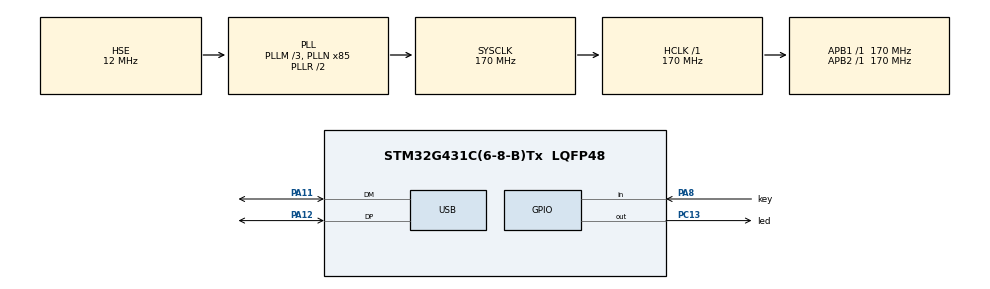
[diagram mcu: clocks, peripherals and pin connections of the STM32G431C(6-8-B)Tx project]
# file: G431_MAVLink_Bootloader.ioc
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CRC.CRCLength=CRC_POLYLENGTH_16B
CRC.DefaultInitValueUse=DEFAULT_INIT_VALUE_DISABLE
CRC.DefaultPolynomialUse=DEFAULT_POLYNOMIAL_DISABLE
CRC.InputDataInversionMode=CRC_INPUTDATA_INVERSION_NONE
CRC.OutputDataInversionMode=CRC_OUTPUTDATA_INVERSION_DISABLE
IWDG.Prescaler=IWDG_PRESCALER_64
IWDG.Reload=500
Mcu.Family=STM32G4
Mcu.Name=STM32G431C(6-8-B)Tx
Mcu.Package=LQFP48
NVIC.PriorityGroup=NVIC_PRIORITYGROUP_4
NVIC.TIM6_DAC_IRQn=true\:10\:0\:true\:false\:true\:true\:true\:true
NVIC.USB_LP_IRQn=true\:0\:0\:false\:false\:true\:false\:true\:true
PA11.Mode=Device
PA11.Signal=USB_DM
PA12.Mode=Device
PA12.Signal=USB_DP
PA13.Mode=Serial_Wire
PA13.Signal=SYS_JTMS-SWDIO
PA14.Mode=Serial_Wire
PA14.Signal=SYS_JTCK-SWCLK
PA8.GPIO_Label=key
PA8.GPIO_PuPd=GPIO_PULLUP
PA8.Signal=GPIO_Input
PC13.GPIO_Label=led
PC13.GPIO_PuPd=GPIO_PULLUP
PC13.PinState=GPIO_PIN_SET
PC13.Signal=GPIO_Output
PF0-OSC_IN.Mode=HSE-External-Oscillator
PF0-OSC_IN.Signal=RCC_OSC_IN
PF1-OSC_OUT.Mode=HSE-External-Oscillator
PF1-OSC_OUT.Signal=RCC_OSC_OUT
ProjectManager.HeapSize=0x200
ProjectManager.StackSize=0x400
ProjectManager.TargetToolchain=CMake
RCC.ADC12Freq_Value=170000000
RCC.AHBFreq_Value=170000000
RCC.APB1Freq_Value=170000000
RCC.APB1TimFreq_Value=170000000
RCC.APB2Freq_Value=170000000
RCC.APB2TimFreq_Value=170000000
RCC.CK48CLockSelection=RCC_USBCLKSOURCE_HSI48
RCC.CortexFreq_Value=170000000
RCC.EXTERNAL_CLOCK_VALUE=12288000
RCC.HCLKFreq_Value=170000000
RCC.HSE_VALUE=12000000
RCC.HSI48_VALUE=48000000
RCC.HSI_VALUE=16000000
RCC.LSE_VALUE=32768
RCC.PLLM=RCC_PLLM_DIV3
RCC.PLLN=85
RCC.PLLSourceVirtual=RCC_PLLSOURCE_HSE
RCC.SYSCLKFreq_VALUE=170000000
RCC.SYSCLKSource=RCC_SYSCLKSOURCE_PLLCLK
RCC.USBFreq_Value=48000000
RCC.VCOOutputFreq_Value=340000000
TIM6.AutoReloadPreload=TIM_AUTORELOAD_PRELOAD_ENABLE
TIM6.Dithering=Disable
TIM6.PeriodNoDither=1000-1
TIM6.Prescaler=170-1
USB_DEVICE.CLASS_NAME_FS=CDC
USB_DEVICE.VirtualMode=Cdc
USB_DEVICE.VirtualModeFS=Cdc_FS
VP_CRC_VS_CRC.Mode=CRC_Activate
VP_IWDG_VS_IWDG.Mode=IWDG_Activate
VP_SYS_VS_DBSignals.Mode=DisableDeadBatterySignals
VP_TIM6_VS_ClockSourceINT.Mode=Enable_Timer
VP_USB_DEVICE_VS_USB_DEVICE_CDC_FS.Mode=CDC_FS
board=custom

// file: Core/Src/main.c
/* USER CODE BEGIN Header */
/**
  ******************************************************************************
  * @file           : main.c
  * @brief          : Main program body
  ******************************************************************************
  * @attention
  *
  * Copyright (c) 2026 STMicroelectronics.
  * All rights reserved.
  *
  * This software is licensed under terms that can be found in the LICENSE file
  * in the root directory of this software component.
  * If no LICENSE file comes with this software, it is provided AS-IS.
  *
  ******************************************************************************
  */
/* USER CODE END Header */
#include "main.h"
#include "crc.h"
#include "iwdg.h"
#include "tim.h"
#include "usb_device.h"
#include "gpio.h"

/* USER CODE BEGIN Includes */
#include "task_fsm.h"
/* USER CODE END Includes */

void SystemClock_Config(void);

int main(void)
{

  /* MCU Configuration--------------------------------------------------------*/

  /* Reset of all peripherals, Initializes the Flash interface and the Systick. */
  HAL_Init();

  /* Configure the system clock */
  SystemClock_Config();

  /* Initialize all configured peripherals */
  MX_GPIO_Init();
  MX_USB_Device_Init();
  MX_CRC_Init();
  MX_IWDG_Init();
  MX_TIM6_Init();
  /* USER CODE BEGIN 2 */
  // 启动1ms定时器
  HAL_TIM_Base_Start_IT(&htim6);

  // 初始化LED
  led = LED_Init(led_GPIO_Port,  led_Pin,  LED_POLARITY_LOW);
  // 初始化LED状态机
  led_fsm = LED_FSM_Init(&led);

  YMODEM_Init(&ymodem_fsm);
  /* USER CODE END 2 */

  /* Infinite loop */
  while (1)
  {

    /* USER CODE BEGIN 3 */
    uint32_t tick = HAL_GetTick();
    static uint32_t tick_iwdg = 0;

    tesk_fsm(&task_fsm, tick);
    // 运行LED状态机
    LED_FSM_Run(&led_fsm, tick);

    // 700ms喂狗(复位周期1000ms)
    if (get_tick_diff(tick, tick_iwdg) >= 700)
    {
      tick_iwdg = tick;
      HAL_IWDG_Refresh(&hiwdg);
    }
  }
  /* USER CODE END 3 */
}

void SystemClock_Config(void)
{
  RCC_OscInitTypeDef RCC_OscInitStruct = {0};
  RCC_ClkInitTypeDef RCC_ClkInitStruct = {0};

  /** Configure the main internal regulator output voltage
  */
  HAL_PWREx_ControlVoltageScaling(PWR_REGULATOR_VOLTAGE_SCALE1_BOOST);

  /** Initializes the RCC Oscillators according to the specified parameters
  * in the RCC_OscInitTypeDef structure.
  */
  RCC_OscInitStruct.OscillatorType = RCC_OSCILLATORTYPE_HSI48|RCC_OSCILLATORTYPE_LSI
                              |RCC_OSCILLATORTYPE_HSE;
  RCC_OscInitStruct.HSEState = RCC_HSE_ON;
  RCC_OscInitStruct.LSIState = RCC_LSI_ON;
  RCC_OscInitStruct.HSI48State = RCC_HSI48_ON;
  RCC_OscInitStruct.PLL.PLLState = RCC_PLL_ON;
  RCC_OscInitStruct.PLL.PLLSource = RCC_PLLSOURCE_HSE;
  RCC_OscInitStruct.PLL.PLLM = RCC_PLLM_DIV3;
  RCC_OscInitStruct.PLL.PLLN = 85;
  RCC_OscInitStruct.PLL.PLLP = RCC_PLLP_DIV2;
  RCC_OscInitStruct.PLL.PLLQ = RCC_PLLQ_DIV2;
  RCC_OscInitStruct.PLL.PLLR = RCC_PLLR_DIV2;
  if (HAL_RCC_OscConfig(&RCC_OscInitStruct) != HAL_OK)
  {
    Error_Handler();
  }

  /** Initializes the CPU, AHB and APB buses clocks
  */
  RCC_ClkInitStruct.ClockType = RCC_CLOCKTYPE_HCLK|RCC_CLOCKTYPE_SYSCLK
                              |RCC_CLOCKTYPE_PCLK1|RCC_CLOCKTYPE_PCLK2;
  RCC_ClkInitStruct.SYSCLKSource = RCC_SYSCLKSOURCE_PLLCLK;
  RCC_ClkInitStruct.AHBCLKDivider = RCC_SYSCLK_DIV1;
  RCC_ClkInitStruct.APB1CLKDivider = RCC_HCLK_DIV1;
  RCC_ClkInitStruct.APB2CLKDivider = RCC_HCLK_DIV1;

  if (HAL_RCC_ClockConfig(&RCC_ClkInitStruct, FLASH_LATENCY_4) != HAL_OK)
  {
    Error_Handler();
  }
}

void Error_Handler(void)
{
  __disable_irq();
  while (1)
  {
  }
}
#ifdef USE_FULL_ASSERT
/**
  * @brief  Reports the name of the source file and the source line number
  *         where the assert_param error has occurred.
  * @param  file: pointer to the source file name
  * @param  line: assert_param error line source number
  * @retval None
  */
void assert_failed(uint8_t *file, uint32_t line)
{
  /* USER CODE BEGIN 6 */
  /* User can add his own implementation to report the file name and line number,
     ex: UART_Send("Wrong parameters value: file %s on line %d\r\n", file, line) */
  /* USER CODE END 6 */
}
#endif /* USE_FULL_ASSERT */
